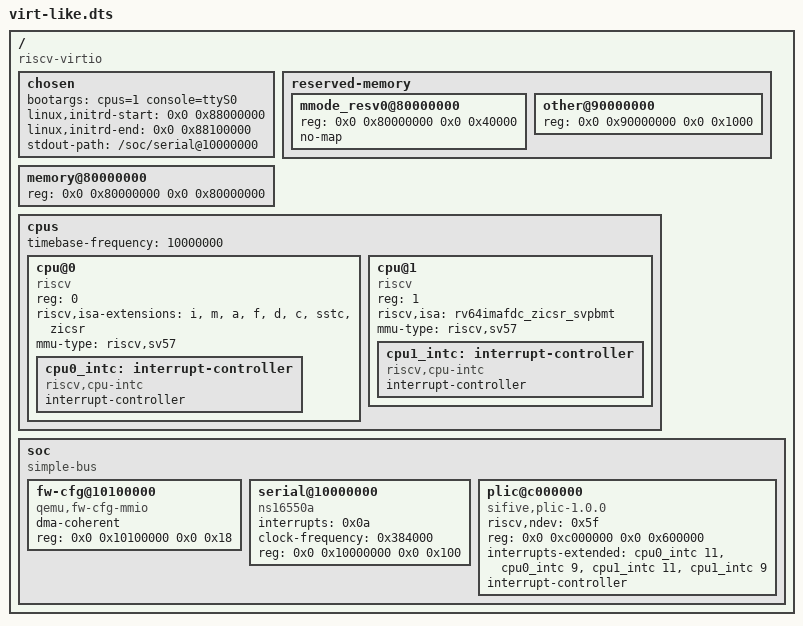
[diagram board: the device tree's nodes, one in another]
/dts-v1/;
/* A hand-written tree in the shape of the emulator's virt machine (two harts). */
/memreserve/ 0x87000000 0x1000;
/ {
	#address-cells = <2>;
	#size-cells = <2>;
	compatible = "riscv-virtio";
	chosen {
		bootargs = "cpus=1 console=ttyS0";
		linux,initrd-start = <0x0 0x88000000>;
		linux,initrd-end = <0x0 0x88100000>;
		stdout-path = "/soc/serial@10000000";
	};
	reserved-memory {
		#address-cells = <2>;
		#size-cells = <2>;
		ranges;
		mmode_resv0@80000000 {
			reg = <0x0 0x80000000 0x0 0x40000>;
			no-map;
		};
		other@90000000 {
			reg = <0x0 0x90000000 0x0 0x1000>;
		};
	};
	memory@80000000 {
		device_type = "memory";
		reg = <0x0 0x80000000 0x0 0x80000000>;
	};
	cpus {
		#address-cells = <1>;
		#size-cells = <0>;
		timebase-frequency = <10000000>;
		cpu@0 {
			device_type = "cpu";
			reg = <0>;
			status = "okay";
			compatible = "riscv";
			riscv,isa-extensions = "i", "m", "a", "f", "d", "c", "sstc", "zicsr";
			mmu-type = "riscv,sv57";
			cpu0_intc: interrupt-controller {
				#interrupt-cells = <1>;
				interrupt-controller;
				compatible = "riscv,cpu-intc";
			};
		};
		cpu@1 {
			device_type = "cpu";
			reg = <1>;
			status = "okay";
			compatible = "riscv";
			riscv,isa = "rv64imafdc_zicsr_svpbmt";
			mmu-type = "riscv,sv57";
			cpu1_intc: interrupt-controller {
				#interrupt-cells = <1>;
				interrupt-controller;
				compatible = "riscv,cpu-intc";
			};
		};
	};
	soc {
		#address-cells = <2>;
		#size-cells = <2>;
		compatible = "simple-bus";
		ranges;
		fw-cfg@10100000 {
			dma-coherent;
			reg = <0x0 0x10100000 0x0 0x18>;
			compatible = "qemu,fw-cfg-mmio";
		};
		serial@10000000 {
			interrupts = <0x0a>;
			clock-frequency = <0x384000>;
			reg = <0x0 0x10000000 0x0 0x100>;
			compatible = "ns16550a";
		};
		plic@c000000 {
			riscv,ndev = <0x5f>;
			reg = <0x0 0xc000000 0x0 0x600000>;
			interrupts-extended = <&cpu0_intc 11 &cpu0_intc 9 &cpu1_intc 11 &cpu1_intc 9>;
			interrupt-controller;
			compatible = "sifive,plic-1.0.0", "riscv,plic0";
		};
	};
};
